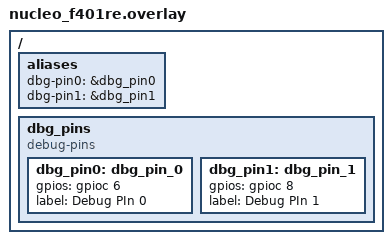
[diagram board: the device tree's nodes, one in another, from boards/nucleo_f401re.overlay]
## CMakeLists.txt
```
# SPDX-License-Identifier: Apache-2.0

cmake_minimum_required(VERSION 3.20.0)

find_package(Zephyr REQUIRED HINTS $ENV{ZEPHYR_BASE})
project(usermode_test)

target_sources(app PRIVATE src/main.c)
```

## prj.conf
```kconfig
# CONFIG THE OPTIMIZATION LEVEL AND OTHER OPTIMIZING FLAGS
CONFIG_DEBUG_OPTIMIZATIONS=y

# INCREMENT MAIN TASK STACK SIZE AND PRIO BECOUSE OF THE SETTINGS SUBSYSTEM WITH NVS
CONFIG_MAIN_STACK_SIZE=4096
CONFIG_MAIN_THREAD_PRIORITY=5

# USE LOG SUBSYSTEM
CONFIG_LOG=y
CONFIG_LOG_MODE_MINIMAL=y

# USE GPIO API
CONFIG_GPIO=y

# USE MPU
CONFIG_MPU=y

# USE USER SPACE
CONFIG_USERSPACE=y
CONFIG_HW_STACK_PROTECTION=y
```

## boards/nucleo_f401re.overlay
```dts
/*
 * Copyright (c) 2024-2025 silvio.vallorani.dev@gmail.com
 *
 * SPDX-License-Identifier: Apache-2.0
 */

 / {
	aliases {
		dbg-pin0 = &dbg_pin0;
		dbg-pin1 = &dbg_pin1;
	};

	dbg_pins: dbg_pins {
		compatible = "debug-pins";
		dbg_pin0: dbg_pin_0 {
			gpios = <&gpioc 6 GPIO_ACTIVE_HIGH>;
			label = "Debug PIn 0";
		};
		dbg_pin1: dbg_pin_1 {
			gpios = <&gpioc 8 GPIO_ACTIVE_HIGH>;
			label = "Debug PIn 1";
		};
	};
};
```

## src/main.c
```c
/*
 * Copyright (c) 2024-2025 silvio.vallorani.dev@gmail.com
 *
 * SPDX-License-Identifier: Apache-2.0
 */

#include <stdio.h>
#include <zephyr/kernel.h>
#include <zephyr/device.h>
#include <zephyr/devicetree.h>
#include <zephyr/drivers/gpio.h>
#include <zephyr/sys/printk.h>
#include <zephyr/sys/libc-hooks.h>

// get the GPIO device
const struct gpio_dt_spec dbg_pin0 = GPIO_DT_SPEC_GET(DT_ALIAS(dbg_pin0), gpios);
const struct gpio_dt_spec dbg_pin1 = GPIO_DT_SPEC_GET(DT_ALIAS(dbg_pin1), gpios);

// Define the stack size and priority
#define THREAD_USERMODE_STACK_SIZE 2048
#define THREAD_USERMODE_PRIORITY 5

// Define the stack for the new thread
K_THREAD_STACK_DEFINE(thread_usermode_stack_area, THREAD_USERMODE_STACK_SIZE);

// Define the thread data structure
struct k_thread thread_usermode_data;
void thread_usermode(void *dummy1, void *dummy2, void *dummy3);
k_tid_t usermode_thread;

int main(void)
{
	__unused int ret;

	// Setup debug pins
	ret = gpio_is_ready_dt(&dbg_pin0);
	ret = gpio_pin_configure_dt(&dbg_pin0, GPIO_OUTPUT_ACTIVE);
	ret = gpio_is_ready_dt(&dbg_pin1);
	ret = gpio_pin_configure_dt(&dbg_pin1, GPIO_OUTPUT_ACTIVE);
	
	// Create the usermode thread in user mode
	usermode_thread = k_thread_create(&thread_usermode_data, thread_usermode_stack_area, THREAD_USERMODE_STACK_SIZE,
					thread_usermode, NULL, NULL, NULL,
					THREAD_USERMODE_PRIORITY, K_USER, K_NO_WAIT);

	// Grant access to the GPIO device to the user mode thread
	k_object_access_grant(dbg_pin1.port, usermode_thread);

	// Start the usermode thread
	k_thread_start(usermode_thread);

	while(1) {
		// Toggle debug pins just to see if the board is working
		ret = gpio_pin_toggle_dt(&dbg_pin0);
		k_msleep(1000);
	}
	
	return 0;
}

void thread_usermode(void *dummy1, void *dummy2, void *dummy3)
{
	__unused int ret;
	
	while(1) {
		ret = gpio_pin_toggle_dt(&dbg_pin1);
		k_msleep(1000);
	}
	
	return;
}
```
